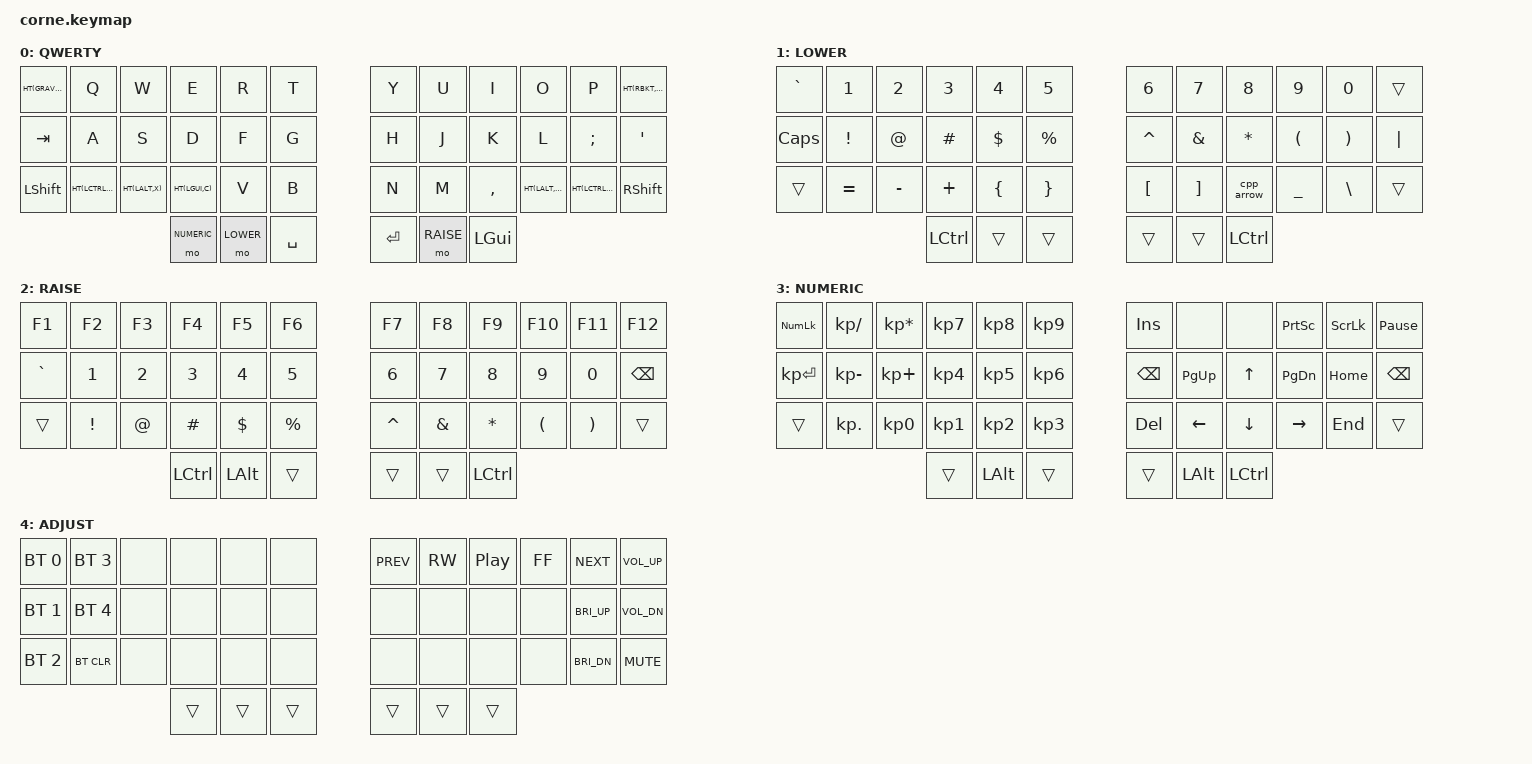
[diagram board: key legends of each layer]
/*
 * Copyright (c) 2020 The ZMK Contributors
 *
 * SPDX-License-Identifier: MIT
 */

#include <behaviors.dtsi>
#include <dt-bindings/zmk/keys.h>
#include <dt-bindings/zmk/bt.h>

#define LOWER 1
#define RAISE 2
#define NUMERIC 3
#define ADJUST 4
#define HT(tap, hold) &key_ht tap hold

/ {
    behaviors {        
        key_ht: key_ht {
            compatible = "zmk,behavior-hold-tap";
            #binding-cells = <2>;
            flavor = "tap-preferred";
            tapping-term-ms = <200>;
            bindings = <&kp>, <&kp>;
        };
        
    };

    macros {
        cpp_arrow: cpp_arrow {
            compatible = "zmk,behavior-macro";
            #binding-cells = <0>;
            wait-ms = <10>;
            tap-ms = <10>;
            bindings = <&kp MINUS &kp GT>;
        };
    };

    conditional_layers {
        compatible = "zmk,conditional-layers";

        adjust {
            if-layers = <LOWER RAISE>;
            then-layer = <ADJUST>;
        };
    };

    keymap {
        compatible = "zmk,keymap";

        default_layer {
            display-name = "QWERTY";
            bindings = <
                HT(GRAVE,ESC) &kp Q       &kp W       &kp E      &kp R   &kp T   &kp Y   &kp U   &kp I     &kp O        &kp P          HT(RBKT,LBKT)
                &kp TAB       &kp A       &kp S       &kp D      &kp F   &kp G   &kp H   &kp J   &kp K     &kp L        &kp SEMI       &kp SQT
                &kp LSHFT     HT(LCTRL,Z) HT(LALT,X)  HT(LGUI,C) &kp V   &kp B   &kp N   &kp M   &kp COMMA HT(LALT,DOT) HT(LCTRL,FSLH) &kp RSHFT
                                             &mo NUMERIC  &mo LOWER  &kp SPACE   &kp RET &mo RAISE  &kp LGUI
            >;
        };

        lower_layer {
            display-name = "LOWER";
            bindings = <
                &kp GRAVE &kp N1    &kp N2    &kp N3    &kp N4   &kp N5      &kp N6    &kp N7   &kp N8    &kp N9    &kp N0   &trans
                &kp CAPS  &kp EXCL  &kp AT    &kp HASH  &kp DLLR &kp PRCNT   &kp CARET &kp AMPS &kp ASTRK &kp LPAR  &kp RPAR &kp PIPE
                &trans    &kp EQUAL &kp MINUS &kp PLUS  &kp LBRC &kp RBRC    &kp LBKT  &kp RBKT &cpp_arrow &kp UNDER &kp BSLH &trans
                                              &kp LCTRL &trans   &trans      &trans    &trans   &kp LCTRL
            >;
        };

        raise_layer {
            display-name = "RAISE";
            bindings = <
                &kp F1    &kp F2    &kp F3    &kp F4    &kp F5   &kp F6      &kp F7    &kp F8   &kp F9    &kp F10   &kp F11  &kp F12
                &kp GRAVE &kp N1    &kp N2    &kp N3    &kp N4   &kp N5      &kp N6    &kp N7   &kp N8    &kp N9    &kp N0   &kp BSPC
                &trans    &kp EXCL  &kp AT    &kp HASH  &kp DLLR &kp PRCNT   &kp CARET &kp AMPS &kp ASTRK &kp LPAR  &kp RPAR &trans
                                              &kp LCTRL &kp LALT   &trans    &trans    &trans   &kp LCTRL
            >;
        };

        numeric_layer {
            display-name = "NUMERIC";
            bindings = <
                &kp KP_NUM   &kp KP_SLASH  &kp KP_ASTERISK &kp KP_N7 &kp KP_N8 &kp KP_N9    &kp INS   &none     &none    &kp PSCRN &kp SLCK  &kp PAUSE_BREAK
                &kp KP_ENTER &kp KP_MINUS  &kp KP_PLUS     &kp KP_N4 &kp KP_N5 &kp KP_N6    &kp BSPC  &kp PG_UP &kp UP   &kp PG_DN  &kp HOME &kp BSPC
                &trans       &kp KP_DOT    &kp KP_N0       &kp KP_N1 &kp KP_N2 &kp KP_N3    &kp DEL   &kp LEFT  &kp DOWN &kp RIGHT  &kp END  &trans
                                                           &trans    &kp LALT    &trans     &trans    &kp LALT  &kp LCTRL
            >;
        };

        adjust_layer {
            display-name = "ADJUST";
            bindings = <
                &bt BT_SEL 0  &bt BT_SEL 3 &none &none  &none  &none    &kp C_PREV &kp C_RW &kp C_PP &kp C_FF &kp C_NEXT    &kp C_VOL_UP
                &bt BT_SEL 1  &bt BT_SEL 4 &none &none  &none  &none    &none      &none    &none    &none    &kp C_BRI_UP  &kp C_VOL_DN
                &bt BT_SEL 2  &bt BT_CLR   &none &none  &none  &none    &none      &none    &none    &none    &kp C_BRI_DN  &kp C_MUTE
                                                 &trans &trans &trans   &trans     &trans   &trans
            >;
        };
    };
};
